# AC7842x register map
Vendor: AutoChips; Series: AC78; File version: 1.0
CPU: CM4 r0p1, little endian, MPU, FPU, VTOR, 4 interrupt priority bits
Registers are 32-bit, read-write, reset 0x0 unless marked. A register's access mark holds for its fields unless they carry their own. Offsets are from the block's base; [hi:lo] are bit positions; {n}, {i} and the like mark numbered series; 'fields as' and 'values as' point back to an identical list.

## GPIOA — General Purpose Input/Output
Base 0x40085000
Same registers: GPIOB 0x40085040, GPIOC 0x40085080, GPIOD 0x400850C0, GPIOE 0x40085100
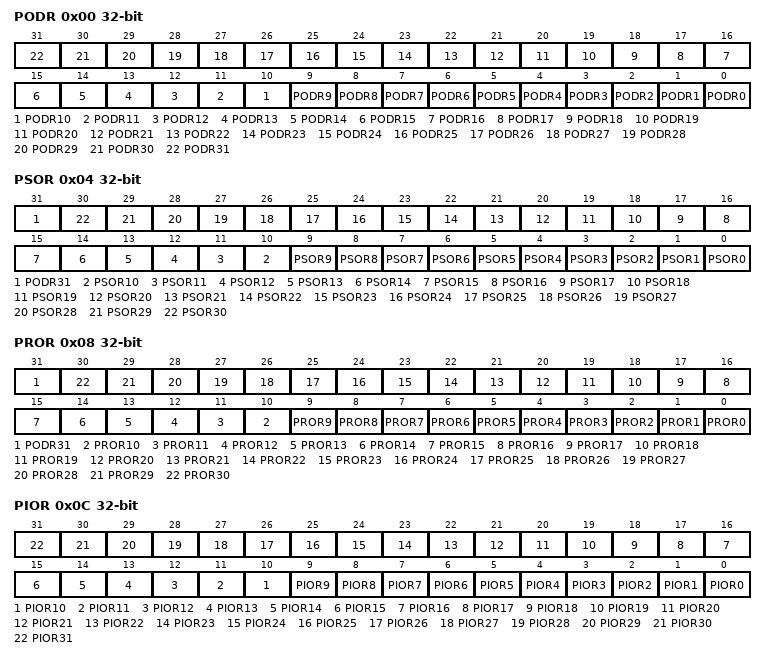
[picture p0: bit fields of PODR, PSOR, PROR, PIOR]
0x00 PODR — PORT Output Data Register
  [n] PODR{n} (n=0..31) — Port output data, bit {n}
0x04 PSOR — PORT Set Output Register
  [31] PODR31 — Port Set Output data, bit 31
  [n] PSOR{n} (n=0..30) — Port Set Output data, bit {n}
0x08 PROR — PORT Reset Output Register
  [31] PODR31 — Port Reset Output data, bit 31
  [n] PROR{n} (n=0..30) — Port Reset Output data, bit {n}
0x0C PIOR — PORT Invert Output Register
  [n] PIOR{n} (n=0..31) — Port Invert Output data, bit {n}
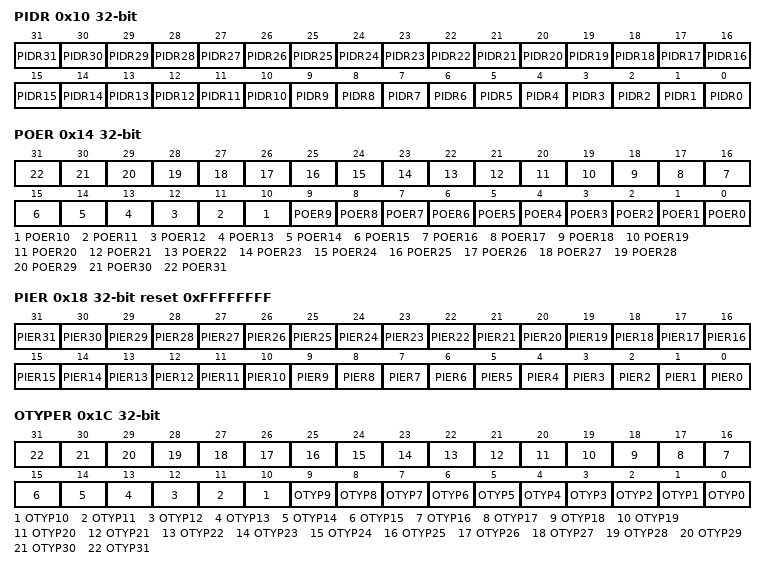
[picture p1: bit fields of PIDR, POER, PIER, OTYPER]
0x10 PIDR — PORT Input Data Register
  [n] PIDR{n} (n=0..31) — Port Input data, bit {n}
0x14 POER — PORT Output Enable Register
  [n] POER{n} (n=0..31) — Port Output Enable, bit {n}
0x18 PIER reset 0xFFFFFFFF — PORT Input Enable Register
  [n] PIER{n} (n=0..31) — Port Input Enable, bit {n}
0x1C OTYPER — PORT Output Type Register
  [n] OTYP{n} (n=0..31) — Port out put type config, bit {n}

## PORTA — Pin Control and Interrupts
Base 0x40085200
Same registers: PORTB 0x40085300, PORTC 0x40085400, PORTD 0x40085500, PORTE 0x40085600
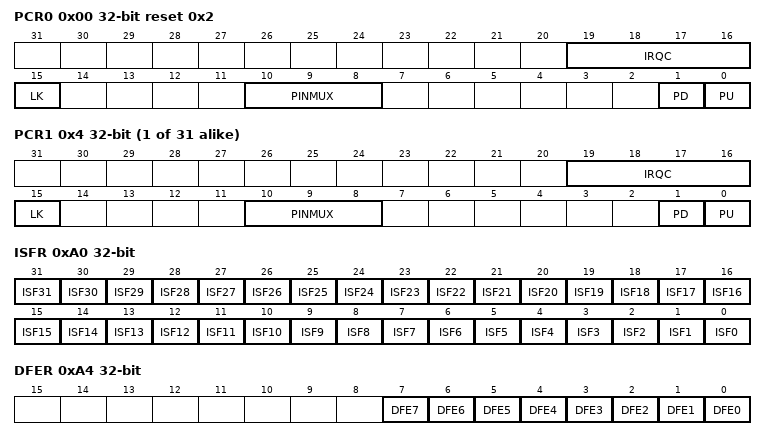
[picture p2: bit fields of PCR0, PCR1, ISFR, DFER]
0x00 PCR0 reset 0x2 — Pin Control Register n
  [19:16] IRQC — Interrupt Configuration
    0=Interrupt Status Flag (ISF) is disabled; 1=ISF flag and DMA request on rising edge; 2=ISF flag and DMA request on falling edge; 3=ISF flag and DMA request on either edge; 8=ISF flag and Interrupt when logic 0; 9=ISF flag and Interrupt on rising-edge; 10=ISF flag and Interrupt on falling-edge; 11=ISF flag and Interrupt on either edge; 12=ISF flag and Interrupt when logic 1
  [15] LK — Lock Register
    0=Pin Control Register fields [15:0] are not locked; 1=Pin Control Register fields [15:0] are locked and cannot be updated until the next system reset
  [10:8] PINMUX — Pin Mux Control
    0=Pin disabled (Alternative 0) (analog); 1=Alternative 1 (GPIO); {v}=Alternative {v} (chip-specific) (v=2..7)
  [1] PD — Pull Down Enable
    0=Internal pulldown resistor is not enabled on the corresponding pin; 1=Internal pulldown resistor is enabled on the corresponding pin, if the pin is configured as a digital input
  [0] PU — Pull Up Enable
    0=Internal pullup resistor is disabled on the corresponding pin; 1=Internal pullup resistor is enabled on the corresponding pin
{0x0+4i} PCR{i} (i=1..31) — Pin Control Register {i}
  fields as PCR0
0xA0 ISFR — Interrupt Status Flag Register
  [all] fields
    0=Configured interrupt is not detected; 1=Configured interrupt is detected. If the pin is configured to generate a DMA request, then the corresponding flag will be cleared automatically at the completion of the requested DMA transfer. Otherwise, the flag remains set until a logic 1 is written to the flag. If the pin is configured for a level sensitive interrupt and the pin remains asserted, then the flag is set again immediately after it is cleared.
  [n] ISF{n} (n=1..31) — Port output data, bit {n}
  [0] ISF0 — Interrupt Status Flag
0xA4 DFER — Digital Filter Enable Register
  [all] fields
    0=Digital filter is disabled on the corresponding pin and output of the digital filter is reset to zero; 1=Digital filter is enabled on the corresponding pin, if the pin is configured as a digital input
  [n] DFE{n} (n=0..7) — Digital Filter Enable
0xA8 DFCR — Digital Filter Clock Register
  [0] CS — Clock Source
    0=Digital filters are clocked by the bus clock; 1=Digital filters are clocked by the LPO clock
0xAC DFWR — Digital Filter Width Register
  [4:0] FILT — Filter Length

## ANA — Analog Control Registers
Base 0x40008800
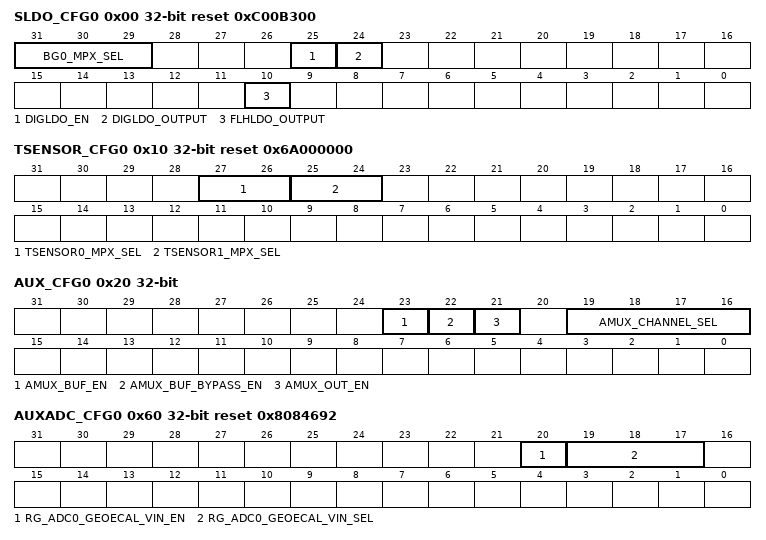
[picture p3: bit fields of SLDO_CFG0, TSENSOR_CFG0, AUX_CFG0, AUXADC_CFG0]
0x00 SLDO_CFG0 reset 0xC00B300 — SLDO Configure Register0
  [31:29] BG0_MPX_SEL — BG0 output select
  [25] DIGLDO_EN — Digital LDO enable
    0=disable; 1=enable
  [24] DIGLDO_OUTPUT — AMUX to ADC enable
    0=disable; 1=enable
  [10] FLHLDO_OUTPUT — Flash LDO output enable
    0=disable; 1=enable
0x10 TSENSOR_CFG0 reset 0x6A000000 — TSENSOR Configuration Register0
  [27:26] TSENSOR0_MPX_SEL — Tsensor0 output
    0=Tsensor0 output off; 3=Tsensor0 output on
  [25:24] TSENSOR1_MPX_SEL — Tsensor1 output
    0=Tsensor1 output off; 3=Tsensor1 output on
0x20 AUX_CFG0 — AUX Configuration Register0
  [23] AMUX_BUF_EN — AMUX BUF enable
    0=disable; 1=enable
  [22] AMUX_BUF_BYPASS_EN — AMUX BUF bypass enable
    0=disable; 1=enable
  [21] AMUX_OUT_EN — AMUX to ADC enable
    0=disable; 1=enable
  [19:16] AMUX_CHANNEL_SEL — AMUX internal channel select
    0=DIGLDO supply channel is selected; 1=FLHLDO supply channel is selected; 2=BG0 channel to ADC0 is selected; 6=BG1 channel to ADC1 is selected; 7=TSENSOR0 channel to ADC0 is selected; 8=TSENSOR1 channel to ADC01is selected; 10=AVDD channel is selected; 11=VDD channel is selected; 15=XOSC supply channel is selected
0x40 BG1_CFG0 — BG1 Configuration Register0
  [31:29] BG1_MPX_SEL — BG1 output select
0x60 AUXADC_CFG0 reset 0x8084692 — AUXADC Configuration Register0
  [20] RG_ADC0_GEOECAL_VIN_EN — GEOE calibration enable
    0=disable; 1=enable
  [19:17] RG_ADC0_GEOECAL_VIN_SEL — GEOE calibration input voltage select
    0=Floating; 1=4*AVDD/16; 2=5*AVDD/16; 3=6*AVDD/16; 4=8*AVDD/16; 5=10*AVDD/16; 6=11*AVDD/16; 7=12*AVDD/16
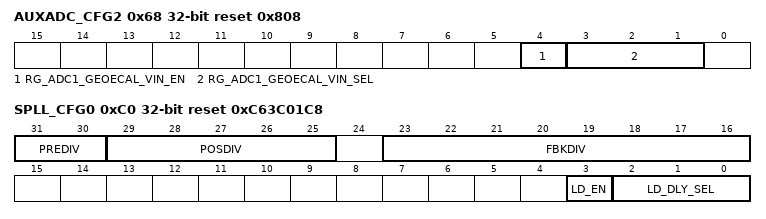
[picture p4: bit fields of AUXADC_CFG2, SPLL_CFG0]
0x68 AUXADC_CFG2 reset 0x808 — AUXADC Configuration Register2
  [4] RG_ADC1_GEOECAL_VIN_EN — GEOE calibration enable
    0=disable; 1=enable
  [3:1] RG_ADC1_GEOECAL_VIN_SEL — GEOE calibration input voltage select
    values as AUXADC_CFG0.RG_ADC0_GEOECAL_VIN_SEL
0xB0 XOSC_CFG0 reset 0x3B0000 — XOSC Configuration Register0
  [15:13] XOSC_LDO_OUTPUT — XOSC output
    0=disable; 1=enable
0xC0 SPLL_CFG0 reset 0xC63C01C8 — System PLL Config 0
  [31:30] PREDIV — PLL Pre-Divider
    {v}=Fref=Fin/{v+1} (v=0..3)
  [29:25] POSDIV — PLL Post-divider Ratio
    0=NONE; 1=VCO/2; 2=VCO/4; 3=VCO/6; 4=VCO/8; 5=VCO/10; 6=VCO/12; 7=VCO/14; 8=VCO/16; 9=VCO/18; 10=VCO/20; 11=VCO/22; 12=VCO/24; 13=VCO/26; 14=VCO/28; 15=VCO/30; 16=VCO/32; 17=VCO/34; 18=VCO/36; 19=VCO/38; 20=VCO/40; 21=VCO/42; 22=VCO/44; 23=VCO/46; 24=VCO/48; 25=VCO/50; 26=VCO/52; 27=VCO/54; 28=VCO/56; 29=VCO/58; 30=VCO/60; 31=VCO/62
  [23:16] FBKDIV — PLL Feedback-Divider
  [3] LD_EN — PLL Lock Detect Enable
    0=DISABLE; 1=ENABLE
  [2:0] LD_DLY_SEL — PLL Lock Detect Comparision Delay Select
    0=64 cycles; 1=128 cycles; 2=256 cycles; 3=1024 cycles
